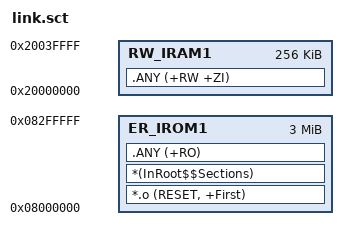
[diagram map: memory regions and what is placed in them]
; *************************************************************
; *** Scatter-Loading Description File for GD32F20x (GD32F207I-EVAL, GD32F207IK) ***
; *************************************************************

LR_IROM1 0x08000000 0x00300000  {    ; load region size_region (3072K Flash)
  ER_IROM1 0x08000000 0x00300000  {  ; load address = execution address
   *.o (RESET, +First)
   *(InRoot$$Sections)
   .ANY (+RO)
  }
  RW_IRAM1 0x20000000 0x00040000  {  ; 256K SRAM
   .ANY (+RW +ZI)
  }
}
